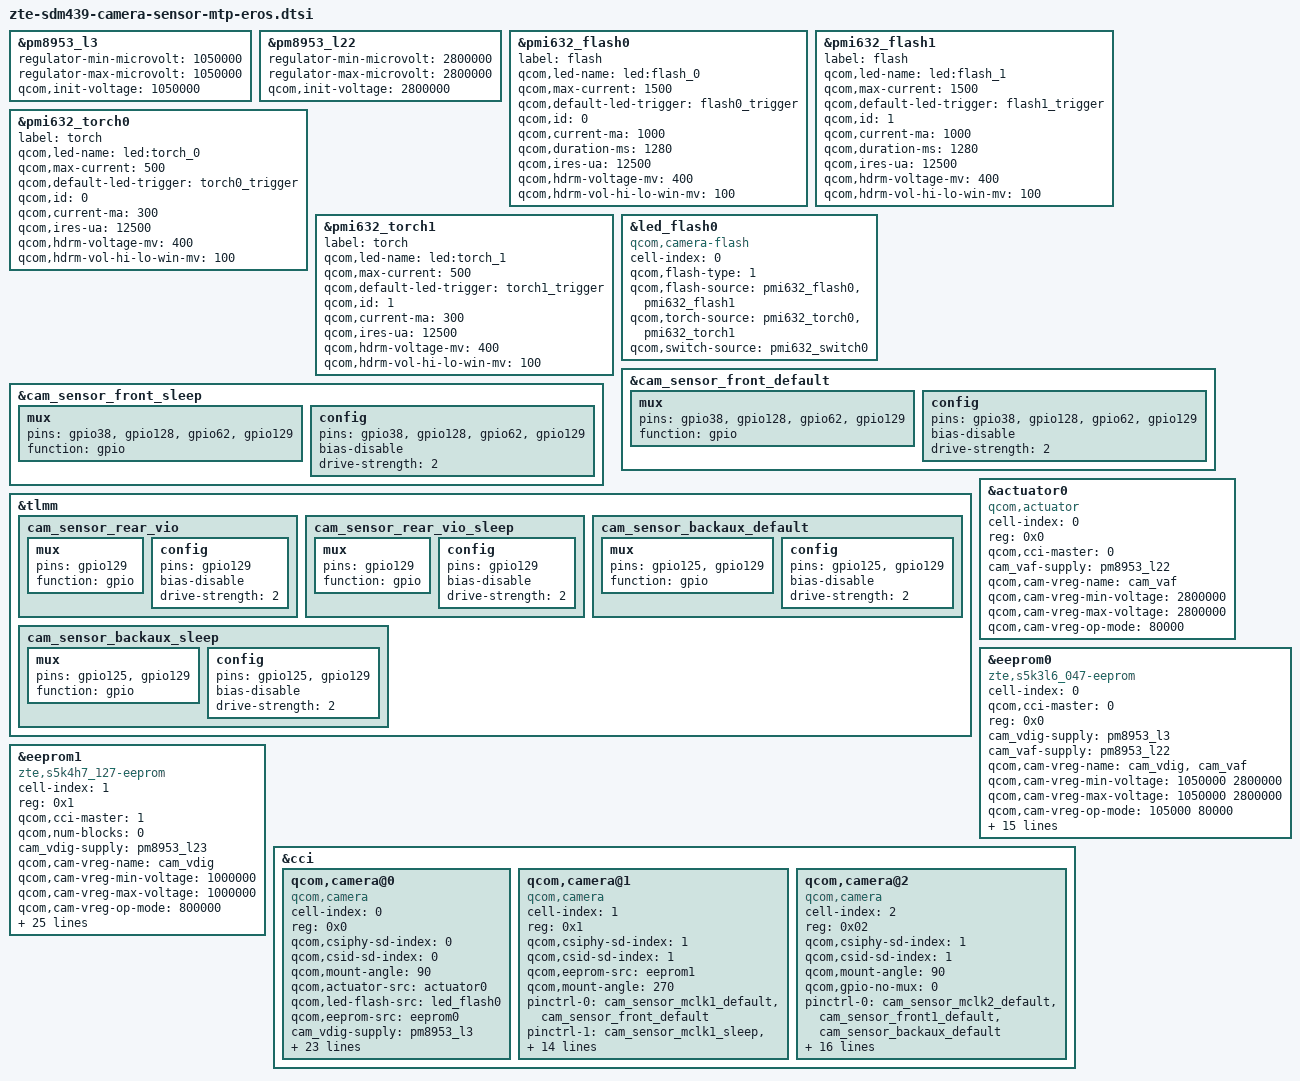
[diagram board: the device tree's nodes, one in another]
/*
 * Copyright (c) 2015-2016, 2018, The Linux Foundation. All rights reserved.
 *
 * This program is free software; you can redistribute it and/or modify
 * it under the terms of the GNU General Public License version 2 and
 * only version 2 as published by the Free Software Foundation.
 *
 * This program is distributed in the hope that it will be useful,
 * but WITHOUT ANY WARRANTY; without even the implied warranty of
 * MERCHANTABILITY or FITNESS FOR A PARTICULAR PURPOSE.  See the
 * GNU General Public License for more details.
 */

#include <dt-bindings/clock/msm-clocks-8952.h>
//#include "../sdm439-regulator.dtsi" //pm8953_l3
//#include "../msm8937-pinctrl.dtsi" //pinctrl
//#include "../pmi632.dtsi"  //flash pmi

&pm8953_l3 {
	regulator-min-microvolt = <1050000>;
	regulator-max-microvolt = <1050000>;
	qcom,init-voltage = <1050000>;
	status = "okay";
};
&pm8953_l22 {
	regulator-min-microvolt = <2800000>;
	regulator-max-microvolt = <2800000>;
	qcom,init-voltage = <2800000>;
	status = "okay";
};
&pmi632_flash0 {
	label = "flash";
	qcom,led-name = "led:flash_0";
	qcom,max-current = <1500>;
	qcom,default-led-trigger = "flash0_trigger";
	qcom,id = <0>;
	qcom,current-ma = <1000>;
	qcom,duration-ms = <1280>;
	qcom,ires-ua = <12500>;
	qcom,hdrm-voltage-mv = <400>;
	qcom,hdrm-vol-hi-lo-win-mv = <100>;
};

&pmi632_flash1 {
	label = "flash";
	qcom,led-name = "led:flash_1";
	qcom,max-current = <1500>;
	qcom,default-led-trigger = "flash1_trigger";
	qcom,id = <1>;
	qcom,current-ma = <1000>;
	qcom,duration-ms = <1280>;
	qcom,ires-ua = <12500>;
	qcom,hdrm-voltage-mv = <400>;
	qcom,hdrm-vol-hi-lo-win-mv = <100>;
};

&pmi632_torch0 {
	label = "torch";
	qcom,led-name = "led:torch_0";
	qcom,max-current = <500>;
	qcom,default-led-trigger = "torch0_trigger";
	qcom,id = <0>;
	qcom,current-ma = <300>;
	qcom,ires-ua = <12500>;
	qcom,hdrm-voltage-mv = <400>;
	qcom,hdrm-vol-hi-lo-win-mv = <100>;
};

&pmi632_torch1 {
	label = "torch";
	qcom,led-name = "led:torch_1";
	qcom,max-current = <500>;
	qcom,default-led-trigger = "torch1_trigger";
	qcom,id = <1>;
	qcom,current-ma = <300>;
	qcom,ires-ua = <12500>;
	qcom,hdrm-voltage-mv = <400>;
	qcom,hdrm-vol-hi-lo-win-mv = <100>;
};
&led_flash0{
	cell-index = <0>;
	compatible = "qcom,camera-flash";
	qcom,flash-type = <1>;
	qcom,flash-source = <&pmi632_flash0 &pmi632_flash1>;
	qcom,torch-source = <&pmi632_torch0 &pmi632_torch1>;
	qcom,switch-source = <&pmi632_switch0>;
};
&cam_sensor_front_default {
	/* RESET AVDD DVDD DOVDD*/
	mux {
		pins = "gpio38","gpio128","gpio62","gpio129";
		function = "gpio";
	};

	config {
		pins = "gpio38","gpio128","gpio62","gpio129";
		bias-disable; /* No PULL */
		drive-strength = <2>; /* 2 MA */
	};
};

&cam_sensor_front_sleep {
	/* RESET AVDD DVDD DOVDD*/
	mux {
		pins = "gpio38","gpio128","gpio62","gpio129";
		function = "gpio";
	};

	config {
		pins = "gpio38","gpio128","gpio62","gpio129";
		bias-disable; /* No PULL */
		drive-strength = <2>; /* 2 MA */
	};
};

&tlmm {
	cam_sensor_rear_vio: cam_sensor_rear_vio {
		/* VANA */
		mux {
			pins = "gpio129";
			function = "gpio";
		};

		config {
			pins = "gpio129";
			bias-disable; /* No PULL */
			drive-strength = <2>; /* 2 MA */
		};
	};

	cam_sensor_rear_vio_sleep: cam_sensor_rear_vio_sleep {
		/* VANA */
		mux {
			pins = "gpio129";
			function = "gpio";
		};

		config {
			pins = "gpio129";
			bias-disable; /* No PULL */
			drive-strength = <2>; /* 2 MA */
		};
	};
	cam_sensor_backaux_default: cam_sensor_backaux_default {
	/* VANA DOVDD*/
		mux {
				pins = "gpio125","gpio129";
				function = "gpio";
		};

		config {
				pins = "gpio125","gpio129";
				bias-disable; /* No PULL */
				drive-strength = <2>; /* 2 MA */
		};
	};

	cam_sensor_backaux_sleep: cam_sensor_backaux_sleep {
	/* VANA DOVDD*/
		mux {
				pins = "gpio125","gpio129";
				function = "gpio";
			};

		config {
				pins = "gpio125","gpio129";
				bias-disable; /* No PULL */
				drive-strength = <2>; /* 2 MA */
			};
	};
};
&actuator0{
	cell-index = <0>;
	reg = <0x0>;
	compatible = "qcom,actuator";
	qcom,cci-master = <0>;
	cam_vaf-supply = <&pm8953_l22>;
	qcom,cam-vreg-name = "cam_vaf";
	qcom,cam-vreg-min-voltage = <2800000>;
	qcom,cam-vreg-max-voltage = <2800000>;
	qcom,cam-vreg-op-mode = <80000>;
};
&eeprom0 {
	cell-index = <0>;
	compatible = "zte,s5k3l6_047-eeprom";
	qcom,cci-master = <0>;
	reg = <0x0>;
	cam_vdig-supply = <&pm8953_l3>;
	cam_vaf-supply = <&pm8953_l22>;
	qcom,cam-vreg-name = "cam_vdig","cam_vaf";
	qcom,cam-vreg-min-voltage = <1050000 2800000>;
	qcom,cam-vreg-max-voltage = <1050000 2800000>;
	qcom,cam-vreg-op-mode = <105000 80000>;
	pinctrl-names = "cam_default", "cam_suspend";
	pinctrl-0 = <&cam_sensor_mclk0_default
			&cam_sensor_rear_reset
			&cam_sensor_rear_vana
			&cam_sensor_rear_vio>;
	pinctrl-1 = <&cam_sensor_mclk0_sleep
			&cam_sensor_rear_reset_sleep
			&cam_sensor_rear_vana_sleep
			&cam_sensor_rear_vio_sleep>;
	gpios = <&tlmm 26 0>,
		<&tlmm 36 0>,
		<&tlmm 35 0>,
		<&tlmm 129 0>;
	qcom,gpio-reset = <1>;
	qcom,gpio-vana = <2>;
	qcom,gpio-vio = <3>;
	qcom,gpio-req-tbl-num = <0 1 2 3>;
	qcom,gpio-req-tbl-flags = <1 0 0 0>;
	qcom,gpio-req-tbl-label = "CAMIF_MCLK0",
		"CAM_RESET0",
		"CAM_VANA",
		"CAM_VIO";
	status = "ok";
};
&eeprom1 {
	cell-index = <1>;
	reg = <0x1>;
	compatible = "zte,s5k4h7_127-eeprom";
	qcom,cci-master = <1>;
	qcom,num-blocks = <0>;
	cam_vdig-supply = <&pm8953_l23>;
	qcom,cam-vreg-name = "cam_vdig";
	qcom,cam-vreg-min-voltage = <1000000>;
	qcom,cam-vreg-max-voltage = <1000000>;
	qcom,cam-vreg-op-mode = <800000>;
	/*qcom,gpio-no-mux = <0>;*/
	pinctrl-names = "cam_default", "cam_suspend";
	pinctrl-0 = <&cam_sensor_mclk1_default
		&cam_sensor_front_default>;
	pinctrl-1 = <&cam_sensor_mclk1_sleep
		&cam_sensor_front_sleep>;
	gpios = <&tlmm 27 0>,
		<&tlmm 38 0>,
		<&tlmm 128 0>,
		<&tlmm 62 0>,
		<&tlmm 129 0>;
	qcom,gpio-reset = <1>;
	qcom,gpio-vana = <2>;
	qcom,gpio-vdig = <3>;
	qcom,gpio-vio = <4>;
	qcom,gpio-req-tbl-num = <0 1 2 3 4>;
	qcom,gpio-req-tbl-flags = <1 0 0 0 0>;
	qcom,gpio-req-tbl-label = "CAMIF_MCLK1",
		"CAM_RESET1",
		"CAM_VANA",
		"CAM_VDIG",
		"CAM_VIO";
	qcom,cam-power-seq-type = "sensor_gpio", "sensor_gpio",
		"sensor_gpio",
		"sensor_gpio", "sensor_clk" , "sensor_gpio";
	qcom,cam-power-seq-val = "sensor_gpio_reset", "sensor_gpio_vio", "sensor_gpio_vana",
		"sensor_gpio_vdig", "sensor_cam_mclk",
		"sensor_gpio_reset";
	qcom,cam-power-seq-cfg-val = <0 1 1 1 24000000 1>;
	qcom,cam-power-seq-delay = <1 1 1 1 1 3>;
	status = "ok";
	clocks = <&clock_gcc clk_mclk1_clk_src>,
			<&clock_gcc clk_gcc_camss_mclk1_clk>;
	clock-names = "cam_src_clk", "cam_clk";
};

&cci {
	/*main camera*/
	qcom,camera@0 {
		cell-index = <0>;
		compatible = "qcom,camera";
		reg = <0x0>;
		qcom,csiphy-sd-index = <0>;
		qcom,csid-sd-index = <0>;
		qcom,mount-angle = <90>;
		qcom,actuator-src = <&actuator0>;
		qcom,led-flash-src = <&led_flash0>;
		qcom,eeprom-src = <&eeprom0>;
		cam_vdig-supply = <&pm8953_l3>;
		cam_vaf-supply = <&pm8953_l22>;
		qcom,cam-vreg-name = "cam_vdig","cam_vaf";
		qcom,cam-vreg-min-voltage = <1050000 2800000>;
		qcom,cam-vreg-max-voltage = <1050000 2800000>;
		qcom,cam-vreg-op-mode = <105000 80000>;
		pinctrl-names = "cam_default", "cam_suspend";
		pinctrl-0 = <&cam_sensor_mclk0_default
				&cam_sensor_rear_reset
				&cam_sensor_rear_vana
				&cam_sensor_rear_vio>;
		pinctrl-1 = <&cam_sensor_mclk0_sleep
				&cam_sensor_rear_reset_sleep
				&cam_sensor_rear_vana_sleep
				&cam_sensor_rear_vio_sleep>;
		gpios = <&tlmm 26 0>,
			<&tlmm 36 0>,
			<&tlmm 35 0>,
			<&tlmm 129 0>;
		qcom,gpio-reset = <1>;
		qcom,gpio-vana = <2>;
		qcom,gpio-vio = <3>;
		qcom,gpio-req-tbl-num = <0 1 2 3>;
		qcom,gpio-req-tbl-flags = <1 0 0 0>;
		qcom,gpio-req-tbl-label = "CAMIF_MCLK0",
			"CAM_RESET0",
			"CAM_VANA",
			"CAM_VIO";
		qcom,sensor-position = <0>;
		qcom,sensor-mode = <0>;
		qcom,cci-master = <0>;
		status = "ok";
	};
    /* front Camera*/
	qcom,camera@1 {
		cell-index = <1>;
		compatible = "qcom,camera";
		reg = <0x1>;
		qcom,csiphy-sd-index = <1>;
		qcom,csid-sd-index = <1>;
		qcom,eeprom-src = <&eeprom1>;
		qcom,mount-angle = <270>;
		/*cam_vdig-supply = <&pm8953_l23>;
		qcom,cam-vreg-name = "cam_vdig";
		qcom,cam-vreg-min-voltage = <1200000>;
		qcom,cam-vreg-max-voltage = <1200000>;
		qcom,cam-vreg-op-mode = <105000>;*/
		pinctrl-names = "cam_default", "cam_suspend";
		pinctrl-0 = <&cam_sensor_mclk1_default
				&cam_sensor_front_default>;
		pinctrl-1 = <&cam_sensor_mclk1_sleep
				&cam_sensor_front_sleep>;
		gpios = <&tlmm 27 0>,
			<&tlmm 38 0>,
			<&tlmm 128 0>,
			<&tlmm 62 0>,
			<&tlmm 129 0>;
		qcom,gpio-reset = <1>;
		qcom,gpio-vana = <2>;
		qcom,gpio-vdig = <3>;
		qcom,gpio-vio = <4>;
		qcom,gpio-req-tbl-num = <0 1 2 3 4>;
		qcom,gpio-req-tbl-flags = <1 0 0 0 0>;
		qcom,gpio-req-tbl-label = "CAMIF_MCLK1",
			"CAM_RESET1",
			"CAM_VANA",
			"CAM_VDIG",
			"CAM_VIO";
		qcom,sensor-position = <1>;
		qcom,sensor-mode = <0>;
		qcom,cci-master = <1>;
		status = "ok";
	};
   /* depth Camera*/
	qcom,camera@2 {
		cell-index = <2>;
		compatible = "qcom,camera";
		reg = <0x02>;
		qcom,csiphy-sd-index = <1>;
		qcom,csid-sd-index = <1>;
		qcom,mount-angle = <90>;
		/*cam_vdig-supply = <&pm8953_l23>;
		qcom,cam-vreg-name = "cam_vdig";
		qcom,cam-vreg-min-voltage = <1200000>;
		qcom,cam-vreg-max-voltage = <1200000>;
		qcom,cam-vreg-op-mode = <200000>;*/
		qcom,gpio-no-mux = <0>;
		pinctrl-names = "cam_default", "cam_suspend";
		pinctrl-0 = <&cam_sensor_mclk2_default
				&cam_sensor_front1_default
				&cam_sensor_backaux_default>;
		pinctrl-1 = <&cam_sensor_mclk2_sleep
				&cam_sensor_front1_sleep
				&cam_sensor_backaux_sleep>;
		gpios = <&tlmm 28 0>,
			<&tlmm 40 0>,
			<&tlmm 39 0>,
			<&tlmm 125 0>,
			<&tlmm 129 0>;
		qcom,gpio-reset = <1>;
		qcom,gpio-standby = <2>;
	    qcom,gpio-vana = <3>;
		qcom,gpio-vio = <4>;
		qcom,gpio-req-tbl-num = <0 1 2 3 4>;
		qcom,gpio-req-tbl-flags = <1 0 0 0 0>;
		qcom,gpio-req-tbl-label = "CAMIF_MCLK2",
			"CAM_RESET2",
			"CAM_STANDBY2",
			"CAM_VANA",
			"CAM_VIO";
		qcom,sensor-position = <2>;
		qcom,sensor-mode = <0>;
		qcom,cci-master = <1>;
		status = "ok";
	};
};
